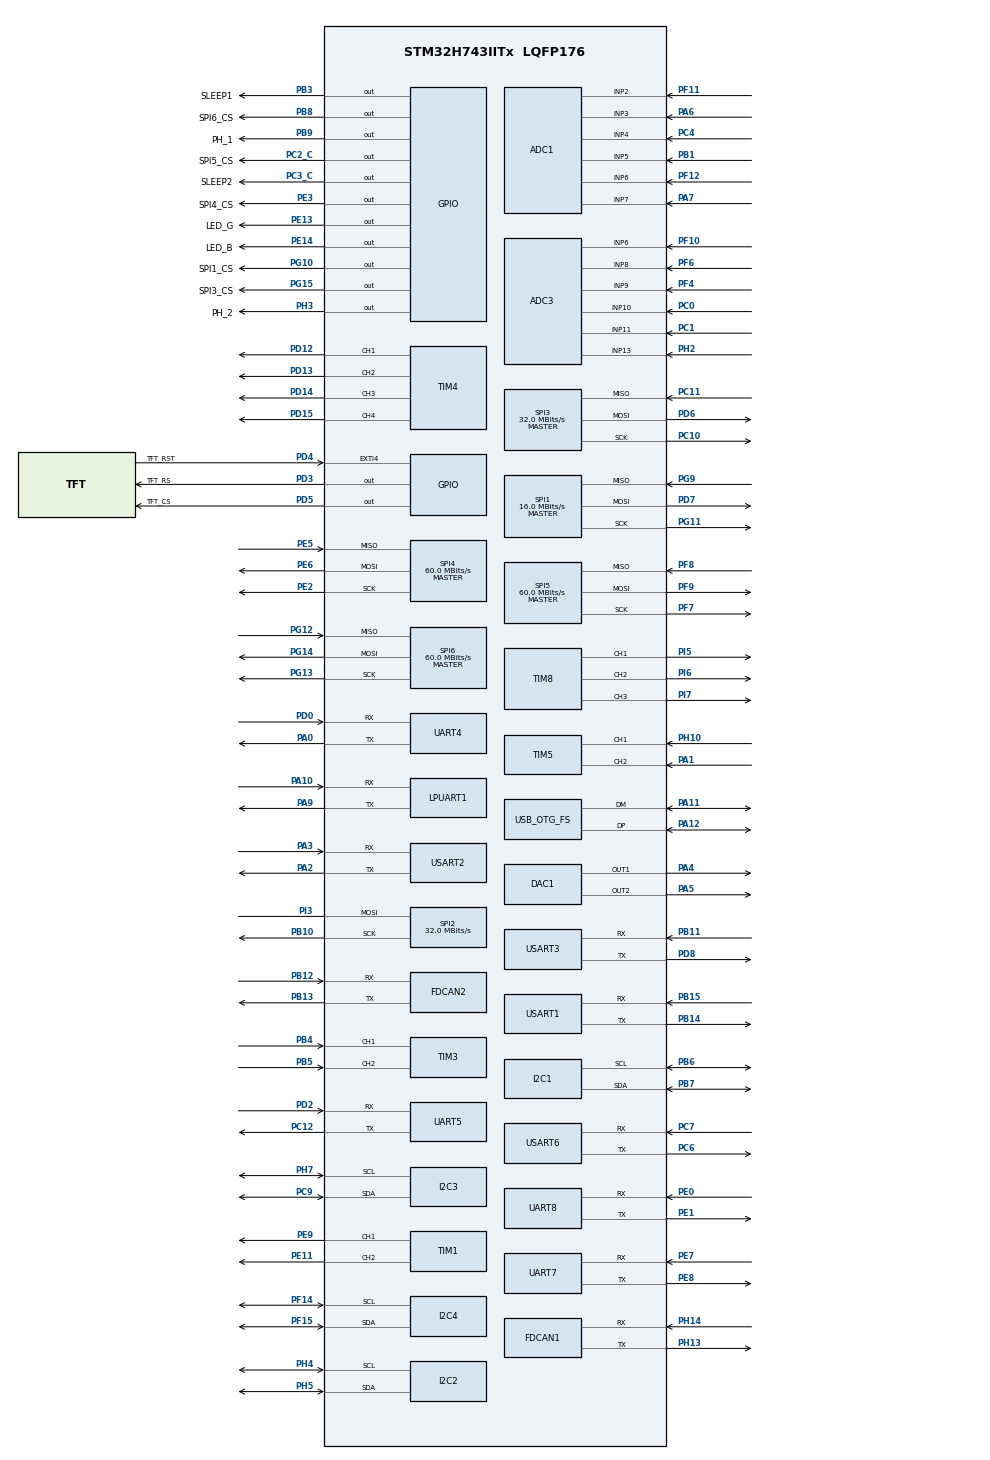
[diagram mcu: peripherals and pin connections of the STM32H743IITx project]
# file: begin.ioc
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ADC1.Channel-1\#ChannelRegularConversion=ADC_CHANNEL_2
ADC1.NbrOfConversionFlag=1
ADC1.OffsetNumber-1\#ChannelRegularConversion=ADC_OFFSET_NONE
ADC1.OffsetSignedSaturation-1\#ChannelRegularConversion=DISABLE
ADC1.Rank-1\#ChannelRegularConversion=1
ADC1.SamplingTime-1\#ChannelRegularConversion=ADC_SAMPLETIME_1CYCLE_5
ADC1.master=1
ADC3.Channel-1\#ChannelRegularConversion=ADC_CHANNEL_6
ADC3.NbrOfConversionFlag=1
ADC3.OffsetNumber-1\#ChannelRegularConversion=ADC_OFFSET_NONE
ADC3.OffsetSignedSaturation-1\#ChannelRegularConversion=DISABLE
ADC3.Rank-1\#ChannelRegularConversion=1
ADC3.SamplingTime-1\#ChannelRegularConversion=ADC_SAMPLETIME_1CYCLE_5
CORTEX_M7.default_mode_Activation=0
DAC1.DAC_Channel-DAC_OUT1_ExtAndInt=DAC_CHANNEL_1
DAC1.DAC_Channel-DAC_OUT2_ExtAndInt=DAC_CHANNEL_2
FDCAN1.CalculateBaudRateNominal=1000000
FDCAN1.CalculateTimeBitNominal=1000
FDCAN1.CalculateTimeQuantumNominal=41.666666666666664
FDCAN1.DataPrescaler=2
FDCAN1.DataSyncJumpWidth=1
FDCAN1.DataTimeSeg1=14
FDCAN1.DataTimeSeg2=5
FDCAN1.NominalPrescaler=1
FDCAN1.NominalTimeSeg1=17
FDCAN1.NominalTimeSeg2=6
FDCAN1.RxFifo0ElmtsNbr=4
FDCAN1.StdFiltersNbr=1
FDCAN1.TxFifoQueueElmtsNbr=4
FDCAN2.CalculateBaudRateNominal=1000000
FDCAN2.CalculateTimeBitNominal=1000
FDCAN2.CalculateTimeQuantumNominal=41.666666666666664
FDCAN2.DataPrescaler=2
FDCAN2.DataTimeSeg1=14
FDCAN2.DataTimeSeg2=5
FDCAN2.MessageRAMOffset=1280
FDCAN2.NominalPrescaler=1
FDCAN2.NominalTimeSeg1=17
FDCAN2.NominalTimeSeg2=6
FDCAN2.RxFifo1ElmtsNbr=4
FDCAN2.StdFiltersNbr=1
FDCAN2.TxFifoQueueElmtsNbr=4
I2C1.Timing=0x307075B1
I2C2.Timing=0x307075B1
I2C3.Timing=0x307075B1
I2C4.Timing=0x307075B1
Mcu.Family=STM32H7
Mcu.Name=STM32H743IITx
Mcu.Package=LQFP176
NVIC.FDCAN1_IT0_IRQn=true\:0\:0\:false\:false\:true\:true\:true\:true
NVIC.FDCAN2_IT1_IRQn=true\:0\:0\:false\:false\:true\:true\:true\:true
NVIC.PriorityGroup=NVIC_PRIORITYGROUP_4
PA0.Mode=Asynchronous
PA0.PinAttribute=Free
PA0.Signal=UART4_TX
PA1.Signal=S_TIM5_CH2
PA10.Mode=Asynchronous
PA10.Signal=LPUART1_RX
PA11.Mode=Device_Only
PA11.Signal=USB_OTG_FS_DM
PA12.Mode=Device_Only
PA12.Signal=USB_OTG_FS_DP
PA13\ (JTMS/SWDIO).Mode=Serial_Wire
PA13\ (JTMS/SWDIO).Signal=DEBUG_JTMS-SWDIO
PA14\ (JTCK/SWCLK).Mode=Serial_Wire
PA14\ (JTCK/SWCLK).Signal=DEBUG_JTCK-SWCLK
PA2.Mode=Asynchronous
PA2.Signal=USART2_TX
PA3.Mode=Asynchronous
PA3.Signal=USART2_RX
PA4.Signal=COMP_DAC11_group
PA5.Signal=COMP_DAC12_group
PA6.Signal=ADCx_INP3
PA7.Signal=ADCx_INP7
PA9.Mode=Asynchronous
PA9.Signal=LPUART1_TX
PB1.Signal=ADCx_INP5
PB10.Mode=Simplex_Bidirectional_Master
PB10.Signal=SPI2_SCK
PB11.Mode=Asynchronous
PB11.Signal=USART3_RX
PB12.Mode=FDCAN_Activate
PB12.Signal=FDCAN2_RX
PB13.Mode=FDCAN_Activate
PB13.Signal=FDCAN2_TX
PB14.Mode=Asynchronous
PB14.Signal=USART1_TX
PB15.Mode=Asynchronous
PB15.Signal=USART1_RX
PB3\ (JTDO/TRACESWO).GPIO_Label=SLEEP1
PB3\ (JTDO/TRACESWO).Signal=GPIO_Output
PB4\ (NJTRST).Signal=S_TIM3_CH1
PB5.PinAttribute=Free
PB5.Signal=S_TIM3_CH2
PB6.Mode=I2C
PB6.PinAttribute=Free
PB6.Signal=I2C1_SCL
PB7.Mode=I2C
PB7.PinAttribute=Free
PB7.Signal=I2C1_SDA
PB8.GPIO_Label=SPI6_CS
PB8.Signal=GPIO_Output
PB9.GPIO_Label=PH_1
PB9.Signal=GPIO_Output
PC0.PinAttribute=Free
PC0.Signal=ADCx_INP10
PC1.PinAttribute=Free
PC1.Signal=ADCx_INP11
PC10.Mode=Full_Duplex_Master
PC10.Signal=SPI3_SCK
PC11.Mode=Full_Duplex_Master
PC11.Signal=SPI3_MISO
PC12.Mode=Asynchronous
PC12.Signal=UART5_TX
PC2_C.GPIO_Label=SPI5_CS
PC2_C.PinAttribute=Free
PC2_C.Signal=GPIO_Output
PC3_C.GPIO_Label=SLEEP2
PC3_C.PinAttribute=Free
PC3_C.Signal=GPIO_Output
PC4.Signal=ADCx_INP4
PC6.Mode=Asynchronous
PC6.Signal=USART6_TX
PC7.Mode=Asynchronous
PC7.Signal=USART6_RX
PC9.Mode=I2C
PC9.Signal=I2C3_SDA
PD0.Mode=Asynchronous
PD0.Signal=UART4_RX
PD12.Signal=S_TIM4_CH1
PD13.Signal=S_TIM4_CH2
PD14.Signal=S_TIM4_CH3
PD15.Signal=S_TIM4_CH4
PD2.Mode=Asynchronous
PD2.Signal=UART5_RX
PD3.GPIO_Label=TFT_RS
PD3.Signal=GPIO_Output
PD4.GPIO_Label=TFT_RST
PD4.Signal=GPXTI4
PD5.GPIO_Label=TFT_CS
PD5.Signal=GPIO_Output
PD6.Mode=Full_Duplex_Master
PD6.Signal=SPI3_MOSI
PD7.Mode=Full_Duplex_Master
PD7.Signal=SPI1_MOSI
PD8.Mode=Asynchronous
PD8.Signal=USART3_TX
PE0.Mode=Asynchronous
PE0.PinAttribute=Free
PE0.Signal=UART8_RX
PE1.Mode=Asynchronous
PE1.PinAttribute=Free
PE1.Signal=UART8_TX
PE11.Signal=S_TIM1_CH2
PE13.GPIO_Label=LED_G
PE13.Signal=GPIO_Output
PE14.GPIO_Label=LED_B
PE14.Signal=GPIO_Output
PE2.Mode=Full_Duplex_Master
PE2.PinAttribute=Free
PE2.Signal=SPI4_SCK
PE3.GPIO_Label=SPI4_CS
PE3.PinAttribute=Free
PE3.Signal=GPIO_Output
PE5.Mode=Full_Duplex_Master
PE5.PinAttribute=Free
PE5.Signal=SPI4_MISO
PE6.Mode=Full_Duplex_Master
PE6.PinAttribute=Free
PE6.Signal=SPI4_MOSI
PE7.Mode=Asynchronous
PE7.Signal=UART7_RX
PE8.Mode=Asynchronous
PE8.Signal=UART7_TX
PE9.Signal=S_TIM1_CH1
PF10.Mode=IN6-Single-Ended
PF10.PinAttribute=Free
PF10.Signal=ADC3_INP6
PF11.Mode=IN2-Single-Ended
PF11.Signal=ADC1_INP2
PF12.Mode=IN6-Single-Ended
PF12.Signal=ADC1_INP6
PF14.Mode=I2C
PF14.Signal=I2C4_SCL
PF15.Mode=I2C
PF15.Signal=I2C4_SDA
PF4.Mode=IN9-Single-Ended
PF4.PinAttribute=Free
PF4.Signal=ADC3_INP9
PF6.Mode=IN8-Single-Ended
PF6.PinAttribute=Free
PF6.Signal=ADC3_INP8
PF7.Mode=Full_Duplex_Master
PF7.PinAttribute=Free
PF7.Signal=SPI5_SCK
PF8.Mode=Full_Duplex_Master
PF8.PinAttribute=Free
PF8.Signal=SPI5_MISO
PF9.Mode=Full_Duplex_Master
PF9.PinAttribute=Free
PF9.Signal=SPI5_MOSI
PG10.GPIO_Label=SPI1_CS
PG10.Signal=GPIO_Output
PG11.Mode=Full_Duplex_Master
PG11.Signal=SPI1_SCK
PG12.Mode=Full_Duplex_Master
PG12.Signal=SPI6_MISO
PG13.Mode=Full_Duplex_Master
PG13.Signal=SPI6_SCK
PG14.Mode=Full_Duplex_Master
PG14.Signal=SPI6_MOSI
PG15.GPIO_Label=SPI3_CS
PG15.Signal=GPIO_Output
PG9.Mode=Full_Duplex_Master
PG9.Signal=SPI1_MISO
PH0-OSC_IN\ (PH0).Mode=HSE-External-Oscillator
PH0-OSC_IN\ (PH0).PinAttribute=Free
PH0-OSC_IN\ (PH0).Signal=RCC_OSC_IN
PH1-OSC_OUT\ (PH1).Mode=HSE-External-Oscillator
PH1-OSC_OUT\ (PH1).PinAttribute=Free
PH1-OSC_OUT\ (PH1).Signal=RCC_OSC_OUT
PH10.Signal=S_TIM5_CH1
PH13.Mode=FDCAN_Activate
PH13.Signal=FDCAN1_TX
PH14.Mode=FDCAN_Activate
PH14.Signal=FDCAN1_RX
PH2.Mode=IN13-Single-Ended
PH2.Signal=ADC3_INP13
PH3.GPIO_Label=PH_2
PH3.Signal=GPIO_Output
PH4.Mode=I2C
PH4.Signal=I2C2_SCL
PH5.Mode=I2C
PH5.Signal=I2C2_SDA
PH7.Mode=I2C
PH7.Signal=I2C3_SCL
PI3.Mode=Simplex_Bidirectional_Master
PI3.Signal=SPI2_MOSI
PI5.Signal=S_TIM8_CH1
PI6.PinAttribute=Free
PI6.Signal=S_TIM8_CH2
PI7.PinAttribute=Free
PI7.Signal=S_TIM8_CH3
ProjectManager.HeapSize=0x1000
ProjectManager.StackSize=0x800
ProjectManager.TargetToolchain=MDK-ARM V5.32
RCC.ADCFreq_Value=78000000
RCC.APB1Freq_Value=120000000
RCC.APB2Freq_Value=120000000
RCC.APB3Freq_Value=120000000
RCC.APB4Freq_Value=120000000
RCC.CortexFreq_Value=480000000
RCC.D1PPRE=RCC_APB3_DIV2
RCC.D2PPRE1=RCC_APB1_DIV2
RCC.D2PPRE2=RCC_APB2_DIV2
RCC.D3PPRE=RCC_APB4_DIV2
RCC.DIVM1=2
RCC.DIVM2=2
RCC.DIVN1=80
RCC.DIVN2=13
RCC.DIVN3=127
RCC.DIVQ1=15
RCC.DIVR1=12
RCC.FDCANCLockSelection=RCC_FDCANCLKSOURCE_HSE
RCC.HCLKFreq_Value=240000000
RCC.HPRE=RCC_HCLK_DIV2
RCC.HSE_VALUE=24000000
RCC.PLL2FRACN=0
RCC.PLL3FRACN=0
RCC.PLLFRACN=0
RCC.PLLSourceVirtual=RCC_PLLSOURCE_HSE
RCC.SYSCLKFreq_VALUE=480000000
RCC.SYSCLKSource=RCC_SYSCLKSOURCE_PLLCLK
RCC.USBFreq_Value=64000000
SH.ADCx_INP10.0=ADC3_INP10,IN10-Single-Ended
SH.ADCx_INP11.0=ADC3_INP11,IN11-Single-Ended
SH.ADCx_INP3.0=ADC1_INP3,IN3-Single-Ended
SH.ADCx_INP4.0=ADC1_INP4,IN4-Single-Ended
SH.ADCx_INP5.0=ADC1_INP5,IN5-Single-Ended
SH.ADCx_INP7.0=ADC1_INP7,IN7-Single-Ended
SH.COMP_DAC11_group.0=DAC1_OUT1,DAC_OUT1_ExtAndInt
SH.COMP_DAC12_group.0=DAC1_OUT2,DAC_OUT2_ExtAndInt
SH.S_TIM1_CH1.0=TIM1_CH1,PWM Generation1 CH1
SH.S_TIM1_CH2.0=TIM1_CH2,PWM Generation2 CH2
SH.S_TIM3_CH1.0=TIM3_CH1,Encoder_Interface
SH.S_TIM3_CH2.0=TIM3_CH2,Encoder_Interface
SH.S_TIM4_CH1.0=TIM4_CH1,PWM Generation1 CH1
SH.S_TIM4_CH2.0=TIM4_CH2,PWM Generation2 CH2
SH.S_TIM4_CH3.0=TIM4_CH3,PWM Generation3 CH3
SH.S_TIM4_CH4.0=TIM4_CH4,PWM Generation4 CH4
SH.S_TIM5_CH1.0=TIM5_CH1,Encoder_Interface
SH.S_TIM5_CH2.0=TIM5_CH2,Encoder_Interface
SH.S_TIM8_CH1.0=TIM8_CH1,PWM Generation1 CH1
SH.S_TIM8_CH2.0=TIM8_CH2,PWM Generation2 CH2
SH.S_TIM8_CH3.0=TIM8_CH3,PWM Generation3 CH3
SPI1.BaudRatePrescaler=SPI_BAUDRATEPRESCALER_4
SPI1.CalculateBaudRate=16.0 MBits/s
SPI1.Direction=SPI_DIRECTION_2LINES
SPI1.Mode=SPI_MODE_MASTER
SPI1.VirtualType=VM_MASTER
SPI2.CalculateBaudRate=32.0 MBits/s
SPI2.Direction=SPI_DIRECTION_1LINE
SPI2.Mode=SPI_MODE_MASTER
SPI2.VirtualType=VM_MASTER
SPI3.CalculateBaudRate=32.0 MBits/s
SPI3.Direction=SPI_DIRECTION_2LINES
SPI3.Mode=SPI_MODE_MASTER
SPI3.VirtualType=VM_MASTER
SPI4.CalculateBaudRate=60.0 MBits/s
SPI4.Direction=SPI_DIRECTION_2LINES
SPI4.Mode=SPI_MODE_MASTER
SPI4.VirtualType=VM_MASTER
SPI5.CalculateBaudRate=60.0 MBits/s
SPI5.Direction=SPI_DIRECTION_2LINES
SPI5.Mode=SPI_MODE_MASTER
SPI5.VirtualType=VM_MASTER
SPI6.CalculateBaudRate=60.0 MBits/s
SPI6.Direction=SPI_DIRECTION_2LINES
SPI6.Mode=SPI_MODE_MASTER
SPI6.VirtualType=VM_MASTER
TIM1.Channel-PWM\ Generation1\ CH1=TIM_CHANNEL_1
TIM1.Channel-PWM\ Generation2\ CH2=TIM_CHANNEL_2
TIM4.Channel-PWM\ Generation1\ CH1=TIM_CHANNEL_1
TIM4.Channel-PWM\ Generation2\ CH2=TIM_CHANNEL_2
TIM4.Channel-PWM\ Generation3\ CH3=TIM_CHANNEL_3
TIM4.Channel-PWM\ Generation4\ CH4=TIM_CHANNEL_4
TIM8.Channel-PWM\ Generation1\ CH1=TIM_CHANNEL_1
TIM8.Channel-PWM\ Generation2\ CH2=TIM_CHANNEL_2
TIM8.Channel-PWM\ Generation3\ CH3=TIM_CHANNEL_3
USART1.VirtualMode-Asynchronous=VM_ASYNC
USART2.VirtualMode-Asynchronous=VM_ASYNC
USART3.VirtualMode-Asynchronous=VM_ASYNC
USART6.VirtualMode-Asynchronous=VM_ASYNC
USB_OTG_FS.VirtualMode=Device_Only
VP_MEMORYMAP_VS_MEMORYMAP.Mode=CurAppReg
VP_TIM1_VS_ClockSourceINT.Mode=Internal
VP_TIM2_VS_ClockSourceINT.Mode=Internal
VP_TIM4_VS_ClockSourceINT.Mode=Internal
VP_TIM8_VS_ClockSourceINT.Mode=Internal
board=custom

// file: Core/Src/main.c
/* USER CODE BEGIN Header */
/**
  ******************************************************************************
  * @file           : main.c
  * @brief          : Main program body
  ******************************************************************************
  * @attention
  *
  * Copyright (c) 2025 STMicroelectronics.
  * All rights reserved.
  *
  * This software is licensed under terms that can be found in the LICENSE file
  * in the root directory of this software component.
  * If no LICENSE file comes with this software, it is provided AS-IS.
  *
  ******************************************************************************
  */
/* USER CODE END Header */
#include "main.h"
#include "adc.h"
#include "dac.h"
#include "fdcan.h"
#include "i2c.h"
#include "usart.h"
#include "memorymap.h"
#include "spi.h"
#include "tim.h"
#include "usb_otg.h"
#include "gpio.h"

/* USER CODE BEGIN Includes */
		 #include "dm_j4310.h"
/* USER CODE END Includes */

void SystemClock_Config(void);
void PeriphCommonClock_Config(void);

int main(void)
{

  /* MCU Configuration--------------------------------------------------------*/

  /* Reset of all peripherals, Initializes the Flash interface and the Systick. */
  HAL_Init();

  /* Configure the system clock */
  SystemClock_Config();

  /* Configure the peripherals common clocks */
  PeriphCommonClock_Config();

  /* Initialize all configured peripherals */
  MX_GPIO_Init();
  MX_FDCAN1_Init();
  MX_FDCAN2_Init();
  MX_I2C1_Init();
  MX_I2C2_Init();
  MX_I2C3_Init();
  MX_I2C4_Init();
  MX_LPUART1_UART_Init();
  MX_UART4_Init();
  MX_UART5_Init();
  MX_UART7_Init();
  MX_UART8_Init();
  MX_USART1_UART_Init();
  MX_USART3_UART_Init();
  MX_USART6_UART_Init();
  MX_SPI1_Init();
  MX_SPI4_Init();
  MX_SPI5_Init();
  MX_SPI6_Init();
  MX_TIM1_Init();
  MX_TIM2_Init();
  MX_TIM3_Init();
  MX_TIM4_Init();
  MX_TIM5_Init();
  MX_TIM8_Init();
  MX_ADC1_Init();
  MX_ADC3_Init();
  MX_DAC1_Init();
  MX_SPI2_Init();
  MX_SPI3_Init();
  MX_USART2_UART_Init();
  MX_USB_OTG_FS_PCD_Init();
  /* USER CODE BEGIN 2 */
	HAL_GPIO_WritePin(LED_G_GPIO_Port,LED_G_Pin,0);
		HAL_GPIO_WritePin(LED_B_GPIO_Port,LED_B_Pin,0);
  DM_4310_Register(&hfdcan2, 0x01, 0x00, pos_vel_mode);
	 DM_4310_Register(&hfdcan2, 0x02, 0x03, pos_vel_mode);
  Enable_DM(DM_J4310_instnce[0]);
		HAL_Delay(10);
	   Enable_DM(DM_J4310_instnce[1]);
	float debug_p;
	float debug_v;
//	 DM_J4310_instnce[0]->dm_controller_instance.P_des=debug_p;
//	 DM_J4310_instnce[0]->dm_controller_instance.V_des=debug_v;
  /* USER CODE END 2 */

  /* Infinite loop */
  /* USER CODE BEGIN WHILE */
  while (1)
  {
		 	 DM_J4310_instnce[0]->dm_controller_instance.P_des=debug_p;
	 DM_J4310_instnce[0]->dm_controller_instance.V_des=debug_v;
			 	 DM_J4310_instnce[1]->dm_controller_instance.P_des=debug_p;
	 DM_J4310_instnce[1]->dm_controller_instance.V_des=debug_v;
		Control_DM( DM_J4310_instnce[0]);
    HAL_Delay(10);
		Control_DM( DM_J4310_instnce[1]);
		 HAL_Delay(10);
    /* USER CODE END WHILE */

  }
}

void SystemClock_Config(void)
{
  RCC_OscInitTypeDef RCC_OscInitStruct = {0};
  RCC_ClkInitTypeDef RCC_ClkInitStruct = {0};

  /** Supply configuration update enable
  */
  HAL_PWREx_ConfigSupply(PWR_LDO_SUPPLY);

  /** Configure the main internal regulator output voltage
  */
  __HAL_PWR_VOLTAGESCALING_CONFIG(PWR_REGULATOR_VOLTAGE_SCALE0);

  while(!__HAL_PWR_GET_FLAG(PWR_FLAG_VOSRDY)) {}

  /** Initializes the RCC Oscillators according to the specified parameters
  * in the RCC_OscInitTypeDef structure.
  */
  RCC_OscInitStruct.OscillatorType = RCC_OSCILLATORTYPE_HSE;
  RCC_OscInitStruct.HSEState = RCC_HSE_ON;
  RCC_OscInitStruct.PLL.PLLState = RCC_PLL_ON;
  RCC_OscInitStruct.PLL.PLLSource = RCC_PLLSOURCE_HSE;
  RCC_OscInitStruct.PLL.PLLM = 2;
  RCC_OscInitStruct.PLL.PLLN = 80;
  RCC_OscInitStruct.PLL.PLLP = 2;
  RCC_OscInitStruct.PLL.PLLQ = 15;
  RCC_OscInitStruct.PLL.PLLR = 12;
  RCC_OscInitStruct.PLL.PLLRGE = RCC_PLL1VCIRANGE_3;
  RCC_OscInitStruct.PLL.PLLVCOSEL = RCC_PLL1VCOWIDE;
  RCC_OscInitStruct.PLL.PLLFRACN = 0;
  if (HAL_RCC_OscConfig(&RCC_OscInitStruct) != HAL_OK)
  {
    Error_Handler();
  }

  /** Initializes the CPU, AHB and APB buses clocks
  */
  RCC_ClkInitStruct.ClockType = RCC_CLOCKTYPE_HCLK|RCC_CLOCKTYPE_SYSCLK
                              |RCC_CLOCKTYPE_PCLK1|RCC_CLOCKTYPE_PCLK2
                              |RCC_CLOCKTYPE_D3PCLK1|RCC_CLOCKTYPE_D1PCLK1;
  RCC_ClkInitStruct.SYSCLKSource = RCC_SYSCLKSOURCE_PLLCLK;
  RCC_ClkInitStruct.SYSCLKDivider = RCC_SYSCLK_DIV1;
  RCC_ClkInitStruct.AHBCLKDivider = RCC_HCLK_DIV2;
  RCC_ClkInitStruct.APB3CLKDivider = RCC_APB3_DIV2;
  RCC_ClkInitStruct.APB1CLKDivider = RCC_APB1_DIV2;
  RCC_ClkInitStruct.APB2CLKDivider = RCC_APB2_DIV2;
  RCC_ClkInitStruct.APB4CLKDivider = RCC_APB4_DIV2;

  if (HAL_RCC_ClockConfig(&RCC_ClkInitStruct, FLASH_LATENCY_4) != HAL_OK)
  {
    Error_Handler();
  }
}

void PeriphCommonClock_Config(void)
{
  RCC_PeriphCLKInitTypeDef PeriphClkInitStruct = {0};

  /** Initializes the peripherals clock
  */
  PeriphClkInitStruct.PeriphClockSelection = RCC_PERIPHCLK_ADC;
  PeriphClkInitStruct.PLL2.PLL2M = 2;
  PeriphClkInitStruct.PLL2.PLL2N = 13;
  PeriphClkInitStruct.PLL2.PLL2P = 2;
  PeriphClkInitStruct.PLL2.PLL2Q = 2;
  PeriphClkInitStruct.PLL2.PLL2R = 2;
  PeriphClkInitStruct.PLL2.PLL2RGE = RCC_PLL2VCIRANGE_3;
  PeriphClkInitStruct.PLL2.PLL2VCOSEL = RCC_PLL2VCOMEDIUM;
  PeriphClkInitStruct.PLL2.PLL2FRACN = 0;
  PeriphClkInitStruct.AdcClockSelection = RCC_ADCCLKSOURCE_PLL2;
  if (HAL_RCCEx_PeriphCLKConfig(&PeriphClkInitStruct) != HAL_OK)
  {
    Error_Handler();
  }
}

void Error_Handler(void)
{
  __disable_irq();
  while (1)
  {
  }
}
